CM_ "AUTOGENERATED FILE, DO NOT EDIT";

CM_ "Imported file _comma.dbc starts here";
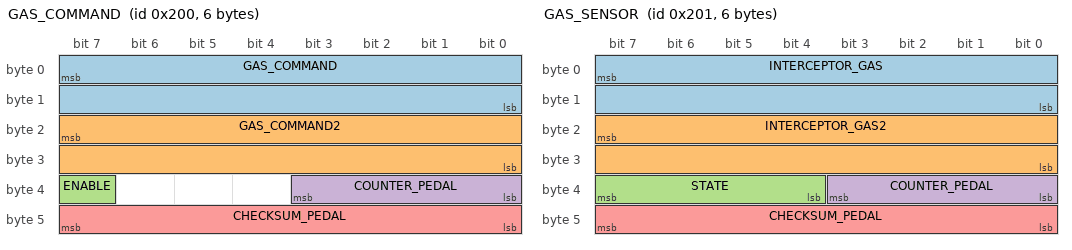
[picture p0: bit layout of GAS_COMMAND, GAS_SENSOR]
BO_ 512 GAS_COMMAND: 6 EON
 SG_ GAS_COMMAND : 7|16@0+ (0.253984064,-83.3) [0|1] "" INTERCEPTOR
 SG_ GAS_COMMAND2 : 23|16@0+ (0.126992032,-83.3) [0|1] "" INTERCEPTOR
 SG_ ENABLE : 39|1@0+ (1,0) [0|1] "" INTERCEPTOR
 SG_ COUNTER_PEDAL : 35|4@0+ (1,0) [0|15] "" INTERCEPTOR
 SG_ CHECKSUM_PEDAL : 47|8@0+ (1,0) [0|255] "" INTERCEPTOR

BO_ 513 GAS_SENSOR: 6 INTERCEPTOR
 SG_ INTERCEPTOR_GAS : 7|16@0+ (1,0) [0|1] "" EON
 SG_ INTERCEPTOR_GAS2 : 23|16@0+ (1,0) [0|1] "" EON
 SG_ STATE : 39|4@0+ (1,0) [0|15] "" EON
 SG_ COUNTER_PEDAL : 35|4@0+ (1,0) [0|15] "" EON
 SG_ CHECKSUM_PEDAL : 47|8@0+ (1,0) [0|255] "" EON

VAL_ 513 STATE 5 "FAULT_TIMEOUT" 4 "FAULT_STARTUP" 3 "FAULT_SCE" 2 "FAULT_SEND" 1 "FAULT_BAD_CHECKSUM" 0 "NO_FAULT" ;

CM_ "Imported file _honda_common.dbc starts here";
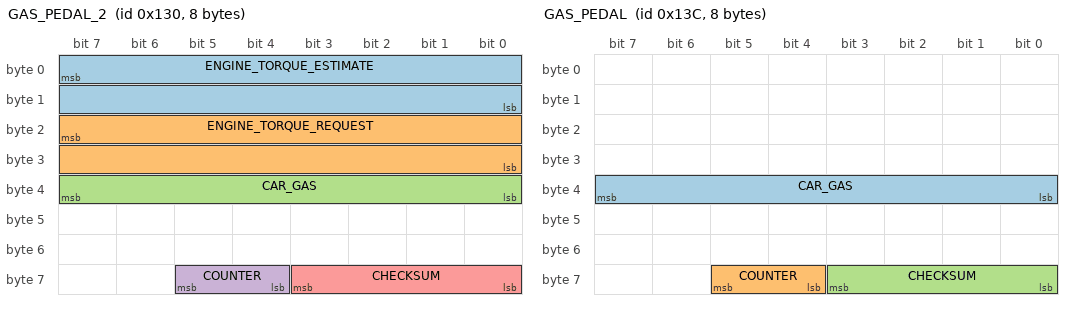
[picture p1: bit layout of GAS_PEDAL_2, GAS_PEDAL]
BO_ 304 GAS_PEDAL_2: 8 PCM
 SG_ ENGINE_TORQUE_ESTIMATE : 7|16@0- (1,0) [-1000|1000] "Nm" EON
 SG_ ENGINE_TORQUE_REQUEST : 23|16@0- (1,0) [-1000|1000] "Nm" EON
 SG_ CAR_GAS : 39|8@0+ (1,0) [0|255] "" EON
 SG_ COUNTER : 61|2@0+ (1,0) [0|3] "" EON
 SG_ CHECKSUM : 59|4@0+ (1,0) [0|15] "" EON

BO_ 316 GAS_PEDAL: 8 PCM
 SG_ CAR_GAS : 39|8@0+ (1,0) [0|255] "" EON
 SG_ COUNTER : 61|2@0+ (1,0) [0|3] "" EON
 SG_ CHECKSUM : 59|4@0+ (1,0) [0|15] "" EON

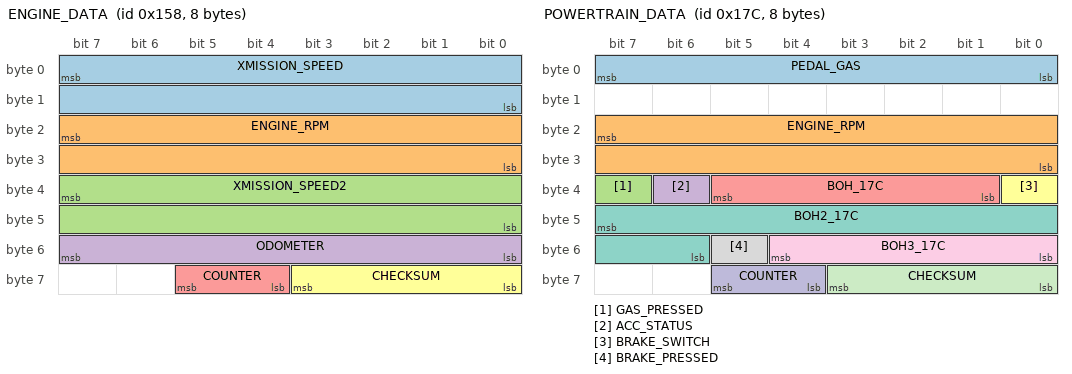
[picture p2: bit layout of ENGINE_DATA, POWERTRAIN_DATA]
BO_ 344 ENGINE_DATA: 8 PCM
 SG_ XMISSION_SPEED : 7|16@0+ (0.01,0) [0|250] "kph" EON
 SG_ ENGINE_RPM : 23|16@0+ (1,0) [0|15000] "rpm" EON
 SG_ XMISSION_SPEED2 : 39|16@0+ (0.01,0) [0|250] "kph" EON
 SG_ ODOMETER : 55|8@0+ (10,0) [0|2550] "m" XXX
 SG_ COUNTER : 61|2@0+ (1,0) [0|3] "" EON
 SG_ CHECKSUM : 59|4@0+ (1,0) [0|15] "" EON

BO_ 380 POWERTRAIN_DATA: 8 PCM
 SG_ PEDAL_GAS : 7|8@0+ (1,0) [0|255] "" EON
 SG_ ENGINE_RPM : 23|16@0+ (1,0) [0|15000] "rpm" EON
 SG_ GAS_PRESSED : 39|1@0+ (1,0) [0|1] "" EON
 SG_ ACC_STATUS : 38|1@0+ (1,0) [0|1] "" EON
 SG_ BOH_17C : 37|5@0+ (1,0) [0|1] "" EON
 SG_ BRAKE_SWITCH : 32|1@0+ (1,0) [0|1] "" EON
 SG_ BOH2_17C : 47|10@0+ (1,0) [0|1] "" EON
 SG_ BRAKE_PRESSED : 53|1@0+ (1,0) [0|1] "" EON
 SG_ BOH3_17C : 52|5@0+ (1,0) [0|1] "" EON
 SG_ COUNTER : 61|2@0+ (1,0) [0|3] "" EON
 SG_ CHECKSUM : 59|4@0+ (1,0) [0|15] "" EON

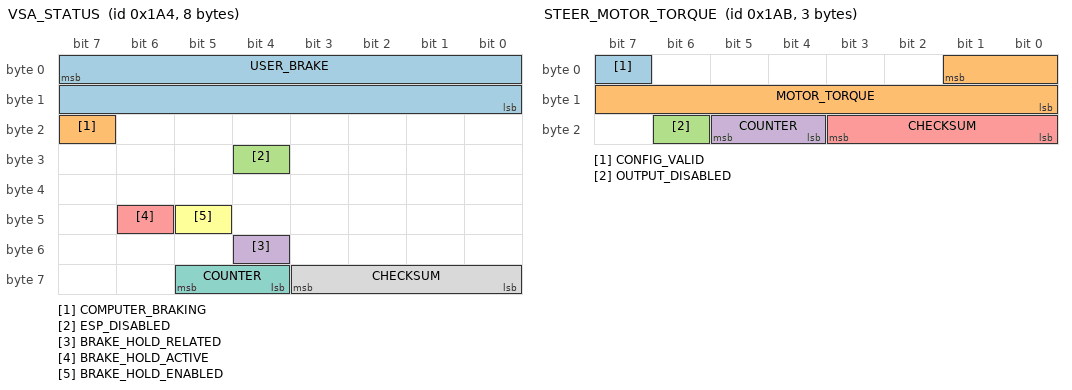
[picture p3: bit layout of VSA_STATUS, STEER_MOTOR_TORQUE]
BO_ 420 VSA_STATUS: 8 VSA
 SG_ USER_BRAKE : 7|16@0+ (0.015625,-1.609375) [0|1000] "" EON
 SG_ COMPUTER_BRAKING : 23|1@0+ (1,0) [0|1] "" EON
 SG_ ESP_DISABLED : 28|1@0+ (1,0) [0|1] "" EON
 SG_ BRAKE_HOLD_RELATED : 52|1@0+ (1,0) [0|1] "" XXX
 SG_ BRAKE_HOLD_ACTIVE : 46|1@0+ (1,0) [0|1] "" EON
 SG_ BRAKE_HOLD_ENABLED : 45|1@0+ (1,0) [0|1] "" EON
 SG_ COUNTER : 61|2@0+ (1,0) [0|3] "" EON
 SG_ CHECKSUM : 59|4@0+ (1,0) [0|15] "" EON

BO_ 427 STEER_MOTOR_TORQUE: 3 EPS
 SG_ CONFIG_VALID : 7|1@0+ (1,0) [0|1] "" EON
 SG_ MOTOR_TORQUE : 1|10@0+ (1,0) [0|256] "" EON
 SG_ OUTPUT_DISABLED : 22|1@0+ (1,0) [0|1] "" EON
 SG_ COUNTER : 21|2@0+ (1,0) [0|3] "" EON
 SG_ CHECKSUM : 19|4@0+ (1,0) [0|15] "" EON

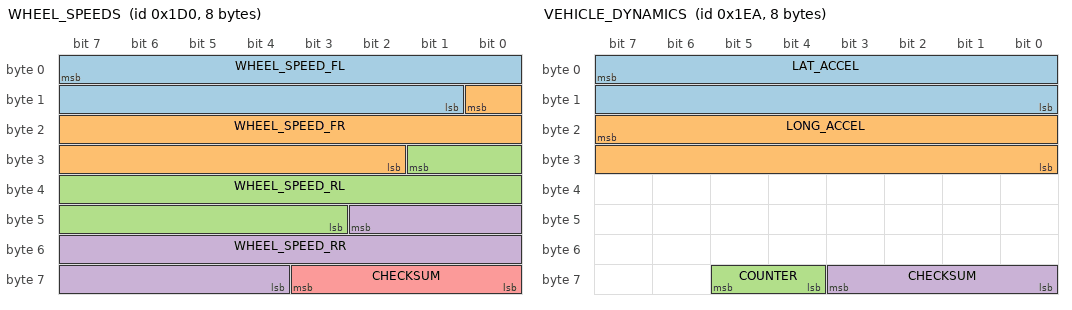
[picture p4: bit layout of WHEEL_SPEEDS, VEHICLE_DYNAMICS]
BO_ 464 WHEEL_SPEEDS: 8 VSA
 SG_ WHEEL_SPEED_FL : 7|15@0+ (0.01,0) [0|250] "kph" EON
 SG_ WHEEL_SPEED_FR : 8|15@0+ (0.01,0) [0|250] "kph" EON
 SG_ WHEEL_SPEED_RL : 25|15@0+ (0.01,0) [0|250] "kph" EON
 SG_ WHEEL_SPEED_RR : 42|15@0+ (0.01,0) [0|250] "kph" EON
 SG_ CHECKSUM : 59|4@0+ (1,0) [0|3] "" EON

BO_ 490 VEHICLE_DYNAMICS: 8 VSA
 SG_ LAT_ACCEL : 7|16@0- (0.0015,0) [-20|20] "m/s2" EON
 SG_ LONG_ACCEL : 23|16@0- (0.0015,0) [-20|20] "m/s2" EON
 SG_ COUNTER : 61|2@0+ (1,0) [0|3] "" EON
 SG_ CHECKSUM : 59|4@0+ (1,0) [0|3] "" EON

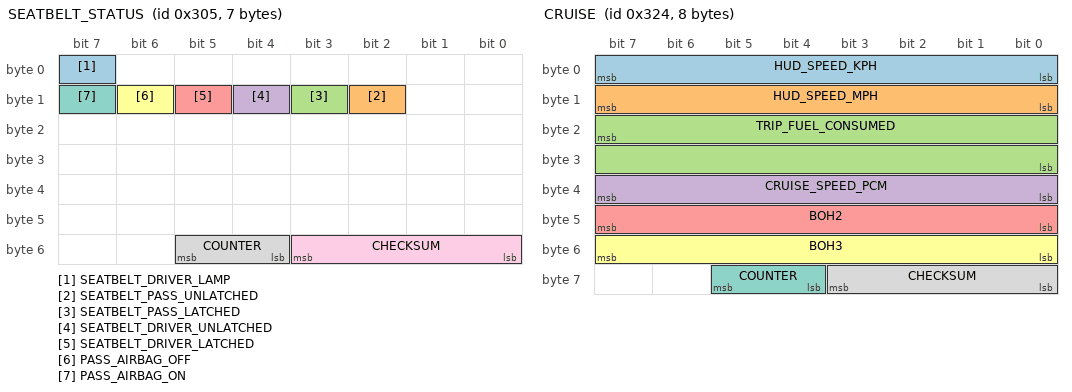
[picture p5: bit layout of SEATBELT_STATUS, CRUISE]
BO_ 773 SEATBELT_STATUS: 7 BDY
 SG_ SEATBELT_DRIVER_LAMP : 7|1@0+ (1,0) [0|1] "" EON
 SG_ SEATBELT_PASS_UNLATCHED : 10|1@0+ (1,0) [0|1] "" EON
 SG_ SEATBELT_PASS_LATCHED : 11|1@0+ (1,0) [0|1] "" EON
 SG_ SEATBELT_DRIVER_UNLATCHED : 12|1@0+ (1,0) [0|1] "" EON
 SG_ SEATBELT_DRIVER_LATCHED : 13|1@0+ (1,0) [0|1] "" EON
 SG_ PASS_AIRBAG_OFF : 14|1@0+ (1,0) [0|1] "" EON
 SG_ PASS_AIRBAG_ON : 15|1@0+ (1,0) [0|1] "" EON
 SG_ COUNTER : 53|2@0+ (1,0) [0|3] "" EON
 SG_ CHECKSUM : 51|4@0+ (1,0) [0|3] "" EON

BO_ 804 CRUISE: 8 PCM
 SG_ HUD_SPEED_KPH : 7|8@0+ (1,0) [0|255] "kph" EON
 SG_ HUD_SPEED_MPH : 15|8@0+ (1,0) [0|255] "mph" EON
 SG_ TRIP_FUEL_CONSUMED : 23|16@0+ (1,0) [0|255] "" EON
 SG_ CRUISE_SPEED_PCM : 39|8@0+ (1,0) [0|255] "" EON
 SG_ BOH2 : 47|8@0- (1,0) [0|255] "" EON
 SG_ BOH3 : 55|8@0+ (1,0) [0|255] "" EON
 SG_ COUNTER : 61|2@0+ (1,0) [0|3] "" EON
 SG_ CHECKSUM : 59|4@0+ (1,0) [0|15] "" EON

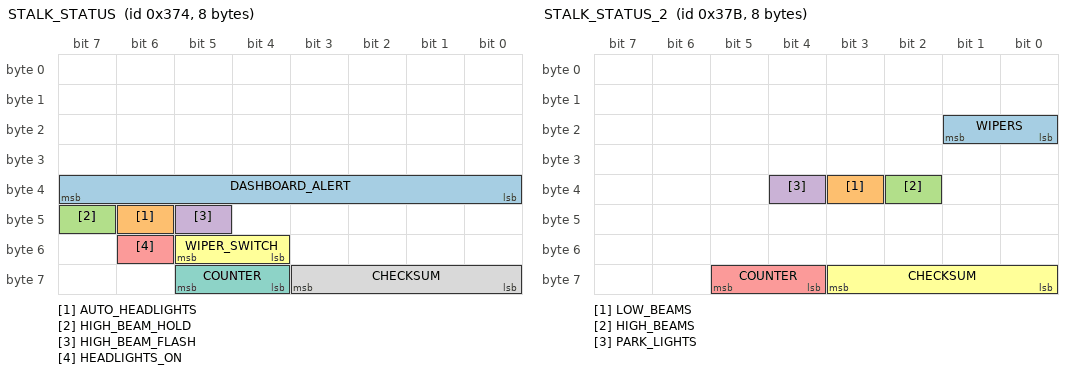
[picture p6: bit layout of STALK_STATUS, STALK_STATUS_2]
BO_ 884 STALK_STATUS: 8 XXX
 SG_ DASHBOARD_ALERT : 39|8@0+ (1,0) [0|255] "" EON
 SG_ AUTO_HEADLIGHTS : 46|1@0+ (1,0) [0|1] "" EON
 SG_ HIGH_BEAM_HOLD : 47|1@0+ (1,0) [0|1] "" EON
 SG_ HIGH_BEAM_FLASH : 45|1@0+ (1,0) [0|1] "" EON
 SG_ HEADLIGHTS_ON : 54|1@0+ (1,0) [0|1] "" EON
 SG_ WIPER_SWITCH : 53|2@0+ (1,0) [0|3] "" XXX
 SG_ COUNTER : 61|2@0+ (1,0) [0|3] "" EON
 SG_ CHECKSUM : 59|4@0+ (1,0) [0|15] "" EON

BO_ 891 STALK_STATUS_2: 8 XXX
 SG_ WIPERS : 17|2@0+ (1,0) [0|3] "" EON
 SG_ LOW_BEAMS : 35|1@0+ (1,0) [0|1] "" XXX
 SG_ HIGH_BEAMS : 34|1@0+ (1,0) [0|1] "" XXX
 SG_ PARK_LIGHTS : 36|1@0+ (1,0) [0|1] "" XXX
 SG_ COUNTER : 61|2@0+ (1,0) [0|3] "" EON
 SG_ CHECKSUM : 59|4@0+ (1,0) [0|15] "" EON

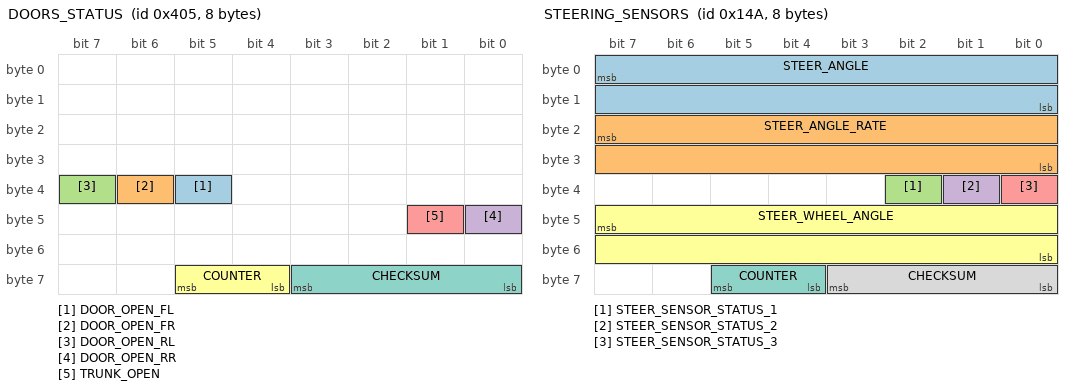
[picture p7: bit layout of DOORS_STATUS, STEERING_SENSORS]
BO_ 1029 DOORS_STATUS: 8 BDY
 SG_ DOOR_OPEN_FL : 37|1@0+ (1,0) [0|1] "" EON
 SG_ DOOR_OPEN_FR : 38|1@0+ (1,0) [0|1] "" EON
 SG_ DOOR_OPEN_RL : 39|1@0+ (1,0) [0|1] "" EON
 SG_ DOOR_OPEN_RR : 40|1@0+ (1,0) [0|1] "" EON
 SG_ TRUNK_OPEN : 41|1@0+ (1,0) [0|1] "" EON
 SG_ COUNTER : 61|2@0+ (1,0) [0|3] "" EON
 SG_ CHECKSUM : 59|4@0+ (1,0) [0|15] "" EON

CM_ SG_ 304 "Seems to be platform-agnostic";
CM_ SG_ 316 "Should exist on Nidec";
CM_ SG_ 420 BRAKE_HOLD_RELATED "On when Brake Hold engaged";
CM_ SG_ 490 LONG_ACCEL "wheel speed derivative, noisy and zero snapping";
CM_ SG_ 773 PASS_AIRBAG_ON "Might just be indicator light";
CM_ SG_ 773 PASS_AIRBAG_OFF "Might just be indicator light";
CM_ SG_ 804 CRUISE_SPEED_PCM "255 = no speed";

VAL_ 884 DASHBOARD_ALERT 0 "none" 51 "acc_problem" 55 "cmbs_problem" 75 "key_not_detected" 79 "fasten_seatbelt" 111 "lkas_problem" 131 "brake_system_problem" 132 "brake_hold_problem" 139 "tbd" 161 "door_open";
VAL_ 891 WIPERS 4 "High" 2 "Low" 0 "Off";

CM_ "honda_civic_ex_2022_can.dbc starts here";

BO_ 330 STEERING_SENSORS: 8 EPS
 SG_ STEER_ANGLE : 7|16@0- (-0.1,0) [-500|500] "deg" EON
 SG_ STEER_ANGLE_RATE : 23|16@0- (-1,0) [-3000|3000] "deg/s" EON
 SG_ STEER_SENSOR_STATUS_1 : 34|1@0+ (1,0) [0|1] "" EON
 SG_ STEER_SENSOR_STATUS_2 : 33|1@0+ (1,0) [0|1] "" EON
 SG_ STEER_SENSOR_STATUS_3 : 32|1@0+ (1,0) [0|1] "" EON
 SG_ STEER_WHEEL_ANGLE : 47|16@0- (-0.1,0) [-500|500] "deg" EON
 SG_ COUNTER : 61|2@0+ (1,0) [0|3] "" EON
 SG_ CHECKSUM : 59|4@0+ (1,0) [0|15] "" EON

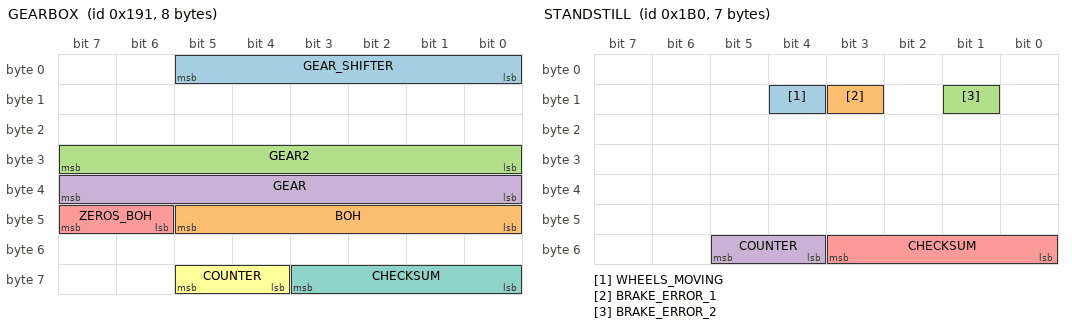
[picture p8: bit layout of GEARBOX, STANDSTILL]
BO_ 401 GEARBOX: 8 PCM
 SG_ GEAR_SHIFTER : 5|6@0+ (1,0) [0|63] "" EON
 SG_ BOH : 45|6@0+ (1,0) [0|63] "" XXX
 SG_ GEAR2 : 31|8@0+ (1,0) [0|1] "" XXX
 SG_ GEAR : 39|8@0+ (1,0) [0|255] "" XXX
 SG_ ZEROS_BOH : 47|2@0+ (1,0) [0|3] "" XXX
 SG_ COUNTER : 61|2@0+ (1,0) [0|3] "" EON
 SG_ CHECKSUM : 59|4@0+ (1,0) [0|15] "" EON

BO_ 432 STANDSTILL: 7 VSA
 SG_ WHEELS_MOVING : 12|1@0+ (1,0) [0|1] "" EON
 SG_ BRAKE_ERROR_1 : 11|1@0+ (1,0) [0|1] "" EON
 SG_ BRAKE_ERROR_2 : 9|1@0+ (1,0) [0|1] "" EON
 SG_ COUNTER : 53|2@0+ (1,0) [0|3] "" EON
 SG_ CHECKSUM : 51|4@0+ (1,0) [0|15] "" EON

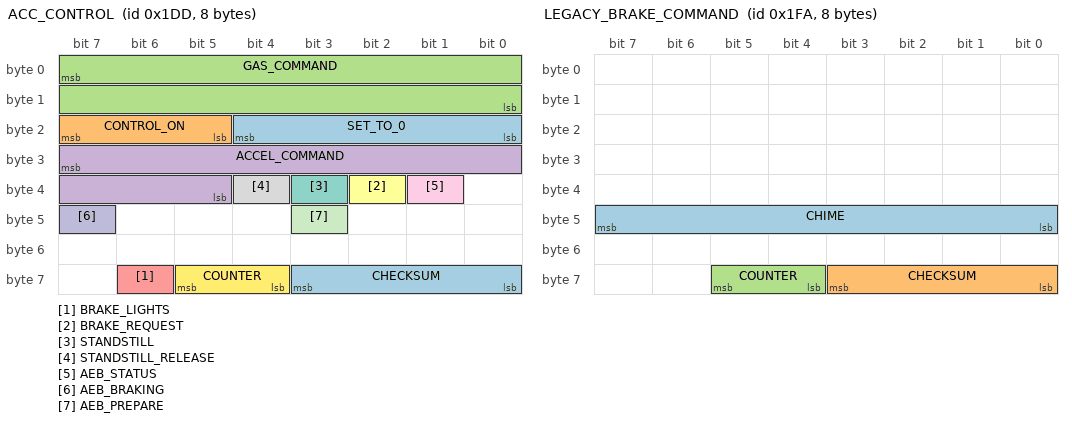
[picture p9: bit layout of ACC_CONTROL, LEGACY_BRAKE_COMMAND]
BO_ 477 ACC_CONTROL: 8 EON
 SG_ SET_TO_0 : 20|5@0+ (1,0) [0|1] "" XXX
 SG_ CONTROL_ON : 23|3@0+ (1,0) [0|5] "" XXX
 SG_ GAS_COMMAND : 7|16@0- (1,0) [0|0] "" XXX
 SG_ ACCEL_COMMAND : 31|11@0- (0.01,0) [0|0] "m/s2" XXX
 SG_ BRAKE_LIGHTS : 62|1@0+ (1,0) [0|1] "" XXX
 SG_ BRAKE_REQUEST : 34|1@0+ (1,0) [0|1] "" XXX
 SG_ STANDSTILL : 35|1@0+ (1,0) [0|1] "" XXX
 SG_ STANDSTILL_RELEASE : 36|1@0+ (1,0) [0|1] "" XXX
 SG_ AEB_STATUS : 33|1@0+ (1,0) [0|1] "" XXX
 SG_ AEB_BRAKING : 47|1@0+ (1,0) [0|1] "" XXX
 SG_ AEB_PREPARE : 43|1@0+ (1,0) [0|1] "" XXX
 SG_ COUNTER : 61|2@0+ (1,0) [0|3] "" XXX
 SG_ CHECKSUM : 59|4@0+ (1,0) [0|15] "" XXX

BO_ 506 LEGACY_BRAKE_COMMAND: 8 ADAS
 SG_ CHIME : 40|8@1+ (1,0) [0|255] "" XXX
 SG_ CHECKSUM : 59|4@0+ (1,0) [0|15] "" XXX
 SG_ COUNTER : 61|2@0+ (1,0) [0|3] "" XXX

BO_ 829 LKAS_HUD: 8 ADAS
 SG_ CAM_TEMP_HIGH : 7|1@0+ (1,0) [0|255] "" BDY
 SG_ SET_ME_X41 : 6|7@0+ (1,0) [0|127] "" BDY
 SG_ BOH : 6|7@0+ (1,0) [0|127] "" BDY
 SG_ DASHED_LANES : 14|1@0+ (1,0) [0|1] "" BDY
 SG_ DTC : 13|1@0+ (1,0) [0|1] "" BDY
 SG_ LKAS_PROBLEM : 12|1@0+ (1,0) [0|1] "" BDY
 SG_ LKAS_OFF : 11|1@0+ (1,0) [0|1] "" BDY
 SG_ SOLID_LANES : 10|1@0+ (1,0) [0|1] "" BDY
 SG_ LDW_RIGHT : 9|1@0+ (1,0) [0|1] "" BDY
 SG_ STEERING_REQUIRED : 8|1@0+ (1,0) [0|1] "" BDY
 SG_ BOH : 23|2@0+ (1,0) [0|4] "" BDY
 SG_ LDW_PROBLEM : 21|1@0+ (1,0) [0|1] "" BDY
 SG_ BEEP : 17|2@0+ (1,0) [0|1] "" BDY
 SG_ LDW_ON : 28|1@0+ (1,0) [0|1] "" BDY
 SG_ LDW_OFF : 27|1@0+ (1,0) [0|1] "" BDY
 SG_ CLEAN_WINDSHIELD : 26|1@0+ (1,0) [0|1] "" BDY
 SG_ SET_ME_X48 : 31|8@0+ (1,0) [0|255] "" BDY
 SG_ LANE_LINES : 36|2@0+ (1,0) [0|3] "" BDY
 SG_ COUNTER : 61|2@0+ (1,0) [0|3] "" BDY
 SG_ CHECKSUM : 59|4@0+ (1,0) [0|15] "" BDY

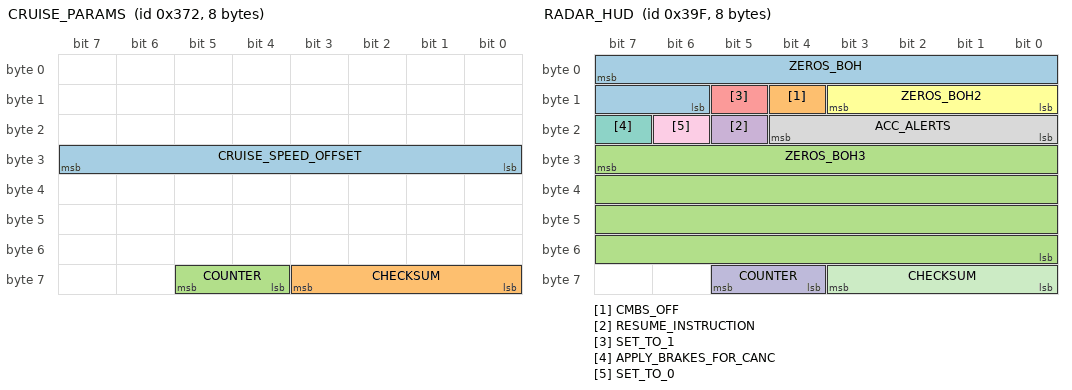
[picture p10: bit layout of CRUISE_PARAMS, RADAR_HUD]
BO_ 882 CRUISE_PARAMS: 8 PCM
 SG_ CRUISE_SPEED_OFFSET : 31|8@0- (0.1,0) [-128|127] "kph" EON
 SG_ CHECKSUM : 59|4@0+ (1,0) [0|3] "" EON
 SG_ COUNTER : 61|2@0+ (1,0) [0|15] "" EON

BO_ 927 RADAR_HUD: 8 RADAR
 SG_ ZEROS_BOH : 7|10@0+ (1,0) [0|127] "" BDY
 SG_ CMBS_OFF : 12|1@0+ (1,0) [0|1] "" BDY
 SG_ ZEROS_BOH3 : 31|32@0+ (1,0) [0|4294967295] "" XXX
 SG_ RESUME_INSTRUCTION : 21|1@0+ (1,0) [0|1] "" XXX
 SG_ SET_TO_1 : 13|1@0+ (1,0) [0|1] "" BDY
 SG_ ZEROS_BOH2 : 11|4@0+ (1,0) [0|1] "" XXX
 SG_ APPLY_BRAKES_FOR_CANC : 23|1@0+ (1,0) [0|1] "" XXX
 SG_ ACC_ALERTS : 20|5@0+ (1,0) [0|1] "" BDY
 SG_ SET_TO_0 : 22|1@0+ (1,0) [0|1] "" XXX
 SG_ COUNTER : 61|2@0+ (1,0) [0|3] "" XXX
 SG_ CHECKSUM : 59|4@0+ (1,0) [0|15] "" XXX

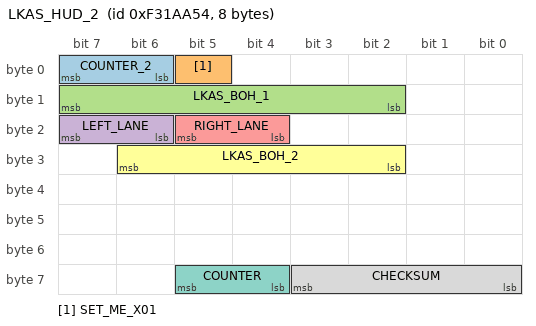
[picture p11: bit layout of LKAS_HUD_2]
BO_ 254913108 LKAS_HUD_2: 8 ADAS
 SG_ COUNTER_2 : 7|2@0+ (1,0) [0|3] "" XXX
 SG_ SET_ME_X01 : 5|1@0+ (1,0) [0|1] "" XXX
 SG_ LKAS_BOH_1 : 15|6@0+ (1,0) [0|63] "" XXX
 SG_ LEFT_LANE : 23|2@0+ (1,0) [0|3] "" XXX
 SG_ RIGHT_LANE : 21|2@0+ (1,0) [0|3] "" XXX
 SG_ LKAS_BOH_2 : 30|5@0+ (1,0) [0|31] "" XXX
 SG_ COUNTER : 61|2@0+ (1,0) [0|3] "" XXX
 SG_ CHECKSUM : 59|4@0+ (1,0) [0|15] "" XXX

VAL_ 401 GEAR_SHIFTER 32 "L" 16 "S" 8 "D" 4 "N" 2 "R" 1 "P";
VAL_ 401 GEAR 7 "L" 10 "S" 4 "D" 3 "N" 2 "R" 1 "P";
